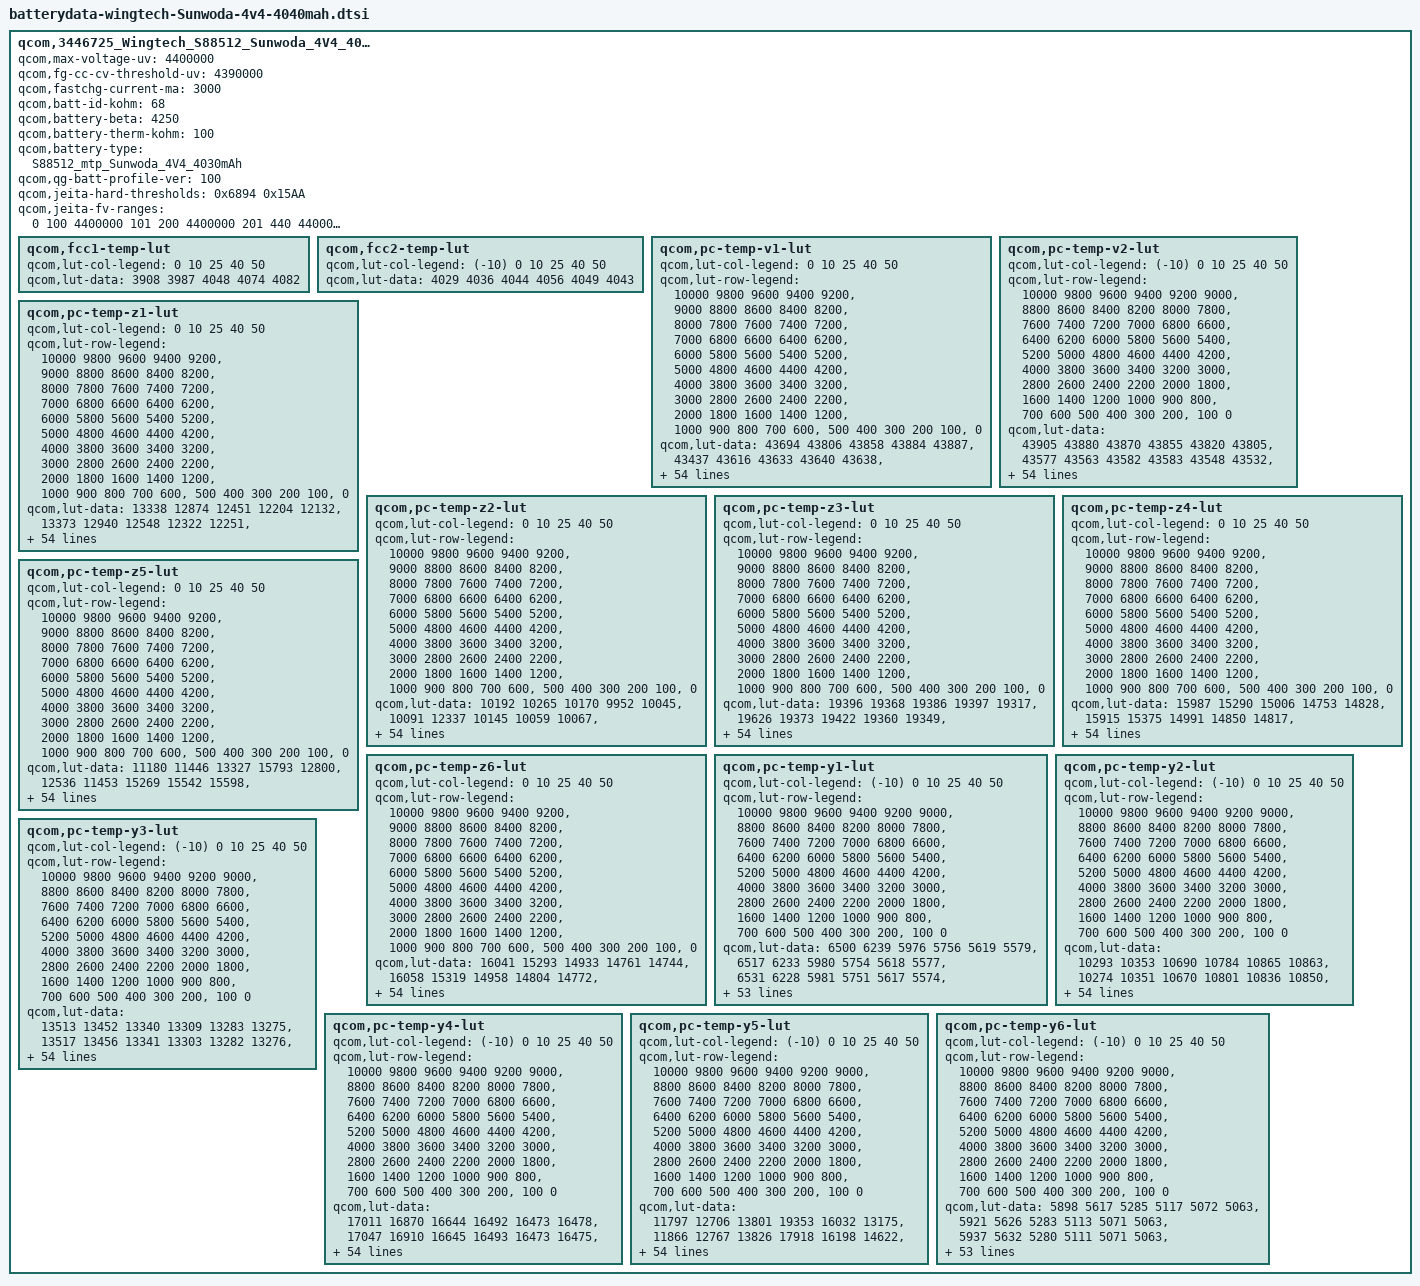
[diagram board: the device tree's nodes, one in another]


qcom,3446725_Wingtech_S88512_Sunwoda_4V4_4040mAh {
	qcom,max-voltage-uv = <4400000>;
	qcom,fg-cc-cv-threshold-uv = <4390000>;
	qcom,fastchg-current-ma = <3000>;
	qcom,batt-id-kohm = <68>;
	qcom,battery-beta = <4250>;
	qcom,battery-therm-kohm = <100>;

	qcom,battery-type = "S88512_mtp_Sunwoda_4V4_4030mAh";
	qcom,qg-batt-profile-ver = <100>;
	/* COLD = 0 DegC, HOT = 60 DegC */
	qcom,jeita-hard-thresholds = <0x6894 0x15AA>;
        qcom,jeita-fv-ranges = <0   100  4400000
                                101 200  4400000
                                201 440  4400000
                                441 580  4100000>;
	qcom,fcc1-temp-lut {
		qcom,lut-col-legend = <0 10 25 40 50>;
		qcom,lut-data = <3908 3987 4048 4074 4082>;
	};

	qcom,fcc2-temp-lut {
		qcom,lut-col-legend = <(-10) 0 10 25 40 50>;
		qcom,lut-data = <4029 4036 4044 4056 4049 4043>;
	};

	qcom,pc-temp-v1-lut {
		qcom,lut-col-legend = <0 10 25 40 50>;
		qcom,lut-row-legend = <10000 9800 9600 9400 9200>,
			<9000 8800 8600 8400 8200>,
			<8000 7800 7600 7400 7200>,
			<7000 6800 6600 6400 6200>,
			<6000 5800 5600 5400 5200>,
			<5000 4800 4600 4400 4200>,
			<4000 3800 3600 3400 3200>,
			<3000 2800 2600 2400 2200>,
			<2000 1800 1600 1400 1200>,
			<1000 900 800 700 600>,
			<500 400 300 200 100>,
			<0>;
		qcom,lut-data = <43694 43806 43858 43884 43887>,
			<43437 43616 43633 43640 43638>,
			<43187 43380 43403 43416 43414>,
			<42946 43129 43165 43189 43191>,
			<42711 42882 42930 42959 42965>,
			<42480 42631 42698 42726 42735>,
			<42253 42396 42467 42493 42503>,
			<42031 42174 42235 42261 42273>,
			<41815 41955 42004 42032 42045>,
			<41603 41729 41778 41806 41818>,
			<41403 41504 41556 41581 41593>,
			<41221 41301 41342 41361 41372>,
			<41036 41122 41139 41149 41155>,
			<40820 40933 40944 40948 40944>,
			<40584 40707 40740 40746 40739>,
			<40362 40473 40526 40538 40538>,
			<40155 40270 40323 40339 40345>,
			<39969 40087 40138 40158 40167>,
			<39818 39921 39964 39989 40000>,
			<39691 39786 39808 39826 39836>,
			<39561 39651 39668 39675 39681>,
			<39425 39448 39501 39507 39512>,
			<39279 39165 39244 39274 39286>,
			<39090 38954 38994 39028 39041>,
			<38858 38832 38848 38866 38872>,
			<38697 38738 38743 38749 38750>,
			<38607 38652 38645 38643 38641>,
			<38540 38577 38548 38538 38536>,
			<38483 38505 38459 38443 38440>,
			<38436 38434 38378 38357 38351>,
			<38392 38369 38306 38280 38270>,
			<38349 38312 38241 38210 38198>,
			<38309 38261 38184 38147 38134>,
			<38271 38215 38133 38088 38073>,
			<38237 38177 38090 38037 38014>,
			<38203 38140 38050 37988 37957>,
			<38173 38104 38009 37938 37896>,
			<38140 38068 37970 37890 37836>,
			<38087 38015 37918 37829 37765>,
			<38001 37929 37835 37740 37670>,
			<37899 37823 37729 37631 37559>,
			<37780 37708 37616 37516 37442>,
			<37642 37574 37485 37387 37314>,
			<37482 37412 37328 37234 37155>,
			<37335 37264 37182 37092 37017>,
			<37244 37167 37085 37002 36941>,
			<37213 37139 37057 36977 36917>,
			<37190 37118 37042 36958 36898>,
			<37176 37104 37025 36938 36879>,
			<37140 37064 36975 36875 36802>,
			<36908 36834 36730 36603 36508>,
			<36467 36401 36294 36159 36060>,
			<35892 35824 35715 35580 35480>,
			<35101 35034 34928 34787 34684>,
			<33856 33800 33689 33551 33441>,
			<30000 30000 30000 30000 30000>;
	};

	qcom,pc-temp-v2-lut {
		qcom,lut-col-legend = <(-10) 0 10 25 40 50>;
		qcom,lut-row-legend = <10000 9800 9600 9400 9200 9000>,
			<8800 8600 8400 8200 8000 7800>,
			<7600 7400 7200 7000 6800 6600>,
			<6400 6200 6000 5800 5600 5400>,
			<5200 5000 4800 4600 4400 4200>,
			<4000 3800 3600 3400 3200 3000>,
			<2800 2600 2400 2200 2000 1800>,
			<1600 1400 1200 1000 900 800>,
			<700 600 500 400 300 200>,
			<100 0>;
		qcom,lut-data = <43905 43880 43870 43855 43820 43805>,
			<43577 43563 43582 43583 43548 43532>,
			<43271 43267 43310 43322 43287 43272>,
			<42993 42992 43054 43072 43039 43025>,
			<42740 42740 42812 42834 42804 42793>,
			<42495 42494 42575 42598 42571 42561>,
			<42257 42251 42340 42364 42337 42327>,
			<42025 42015 42109 42133 42104 42095>,
			<41801 41788 41882 41904 41875 41866>,
			<41583 41568 41659 41677 41649 41640>,
			<41372 41355 41439 41453 41425 41416>,
			<41172 41152 41223 41231 41204 41197>,
			<40974 40952 41013 41015 40989 40982>,
			<40777 40757 40821 40815 40788 40775>,
			<40575 40563 40638 40622 40594 40574>,
			<40322 40345 40431 40419 40396 40379>,
			<39957 40087 40190 40203 40191 40190>,
			<39629 39837 39958 40005 39998 40008>,
			<39440 39627 39765 39846 39838 39842>,
			<39293 39432 39585 39694 39684 39680>,
			<39141 39239 39385 39496 39494 39488>,
			<38985 39042 39165 39247 39261 39261>,
			<38836 38865 38969 39026 39046 39050>,
			<38695 38711 38805 38846 38861 38866>,
			<38561 38572 38661 38690 38699 38704>,
			<38429 38445 38536 38561 38569 38572>,
			<38297 38328 38425 38452 38460 38461>,
			<38192 38223 38324 38352 38359 38360>,
			<38117 38125 38231 38261 38266 38265>,
			<38055 38040 38145 38178 38180 38178>,
			<37999 37981 38067 38102 38105 38100>,
			<37947 37935 37994 38030 38036 38028>,
			<37897 37892 37931 37962 37970 37961>,
			<37846 37852 37874 37897 37909 37902>,
			<37796 37812 37823 37834 37843 37835>,
			<37747 37770 37779 37772 37755 37734>,
			<37698 37727 37738 37708 37655 37612>,
			<37646 37678 37687 37636 37562 37506>,
			<37588 37621 37623 37554 37473 37413>,
			<37524 37553 37551 37473 37387 37325>,
			<37448 37464 37466 37400 37311 37246>,
			<37358 37356 37367 37313 37225 37160>,
			<37240 37235 37251 37195 37110 37047>,
			<37126 37098 37114 37062 36978 36912>,
			<37024 36952 36959 36924 36858 36799>,
			<36950 36871 36911 36892 36827 36770>,
			<36913 36838 36891 36875 36813 36757>,
			<36880 36808 36872 36854 36799 36742>,
			<36834 36763 36834 36821 36767 36709>,
			<36757 36676 36751 36728 36654 36581>,
			<36557 36455 36497 36416 36323 36227>,
			<36135 36007 36017 35915 35814 35712>,
			<35527 35377 35378 35257 35155 35046>,
			<34662 34511 34489 34334 34227 34127>,
			<33285 33205 33210 32889 32876 32707>,
			<27763 27651 27674 27756 27524 27449>;
	};

	qcom,pc-temp-z1-lut {
		qcom,lut-col-legend = <0 10 25 40 50>;
		qcom,lut-row-legend = <10000 9800 9600 9400 9200>,
			<9000 8800 8600 8400 8200>,
			<8000 7800 7600 7400 7200>,
			<7000 6800 6600 6400 6200>,
			<6000 5800 5600 5400 5200>,
			<5000 4800 4600 4400 4200>,
			<4000 3800 3600 3400 3200>,
			<3000 2800 2600 2400 2200>,
			<2000 1800 1600 1400 1200>,
			<1000 900 800 700 600>,
			<500 400 300 200 100>,
			<0>;
		qcom,lut-data = <13338 12874 12451 12204 12132>,
			<13373 12940 12548 12322 12251>,
			<13396 12959 12562 12331 12273>,
			<13404 12964 12564 12334 12275>,
			<13406 12960 12562 12335 12274>,
			<13404 12955 12557 12333 12274>,
			<13396 12948 12551 12332 12273>,
			<13387 12933 12544 12329 12273>,
			<13377 12922 12536 12326 12274>,
			<13367 12918 12532 12325 12274>,
			<13360 12914 12532 12325 12274>,
			<13356 12912 12532 12325 12274>,
			<13353 12914 12530 12324 12274>,
			<13346 12914 12528 12324 12273>,
			<13331 12897 12526 12323 12272>,
			<13315 12876 12522 12322 12273>,
			<13297 12874 12519 12322 12273>,
			<13283 12881 12521 12321 12273>,
			<13288 12886 12522 12321 12274>,
			<13305 12886 12524 12322 12275>,
			<13313 12886 12529 12324 12276>,
			<13307 12887 12531 12326 12278>,
			<13300 12890 12532 12327 12278>,
			<13307 12894 12533 12328 12279>,
			<13334 12898 12536 12330 12281>,
			<13346 12903 12540 12334 12286>,
			<13331 12904 12545 12338 12290>,
			<13315 12905 12553 12341 12292>,
			<13315 12906 12561 12345 12294>,
			<13320 12910 12565 12349 12297>,
			<13325 12913 12567 12353 12301>,
			<13329 12919 12569 12357 12305>,
			<13335 12926 12572 12361 12308>,
			<13337 12932 12575 12365 12311>,
			<13341 12939 12581 12370 12315>,
			<13344 12943 12589 12376 12320>,
			<13344 12945 12593 12381 12324>,
			<13346 12950 12595 12385 12328>,
			<13352 12954 12599 12389 12331>,
			<13361 12958 12605 12393 12335>,
			<13371 12961 12612 12397 12338>,
			<13387 12965 12617 12401 12341>,
			<13402 12973 12622 12404 12344>,
			<13422 12979 12627 12408 12347>,
			<13419 12983 12629 12412 12350>,
			<13410 12984 12632 12415 12351>,
			<13403 12992 12633 12415 12351>,
			<13416 12992 12634 12415 12353>,
			<13404 12975 12631 12419 12356>,
			<13413 12982 12635 12420 12361>,
			<13435 12992 12638 12428 12367>,
			<13428 13003 12655 12435 12372>,
			<13433 13018 12668 12446 12381>,
			<13449 13049 12680 12456 12391>,
			<13449 13049 12680 12456 12391>,
			<13449 13049 12680 12456 12391>;
	};

	qcom,pc-temp-z2-lut {
		qcom,lut-col-legend = <0 10 25 40 50>;
		qcom,lut-row-legend = <10000 9800 9600 9400 9200>,
			<9000 8800 8600 8400 8200>,
			<8000 7800 7600 7400 7200>,
			<7000 6800 6600 6400 6200>,
			<6000 5800 5600 5400 5200>,
			<5000 4800 4600 4400 4200>,
			<4000 3800 3600 3400 3200>,
			<3000 2800 2600 2400 2200>,
			<2000 1800 1600 1400 1200>,
			<1000 900 800 700 600>,
			<500 400 300 200 100>,
			<0>;
		qcom,lut-data = <10192 10265 10170 9952 10045>,
			<10091 12337 10145 10059 10067>,
			<10028 11693 10192 10034 10063>,
			<10013 10970 10199 10065 10046>,
			<10005 10521 10207 10092 10035>,
			<9995 10170 10408 10079 10034>,
			<9982 10128 10629 10050 10034>,
			<9970 10321 10538 10034 10031>,
			<9964 10461 10255 10022 10016>,
			<9959 10332 10174 10017 10005>,
			<9958 10114 10403 10017 10014>,
			<9960 10100 10602 10017 10032>,
			<9961 10272 10589 10019 10042>,
			<9960 10382 10555 10027 10049>,
			<9955 10291 10549 10033 10056>,
			<9954 10156 10563 10036 10065>,
			<9971 10136 10572 10037 10073>,
			<9997 10145 10423 10039 10077>,
			<10017 10157 10205 10043 10080>,
			<10037 10177 10176 10052 10087>,
			<10053 10196 10180 10085 10109>,
			<10065 10200 10187 10110 10132>,
			<10075 10201 10220 10118 10148>,
			<10086 10201 10255 10123 10160>,
			<10095 10200 10263 10119 10155>,
			<10105 10200 10266 10109 10112>,
			<10113 10202 10267 10101 10066>,
			<10121 10208 10265 10100 10021>,
			<10125 10211 10260 10098 9985>,
			<10128 10206 10246 10083 9976>,
			<10132 10201 10224 10055 9971>,
			<10140 10202 10220 10041 9971>,
			<10149 10205 10236 10036 9981>,
			<10153 10210 10253 10039 9999>,
			<10156 10219 10266 10061 10024>,
			<10160 10232 10278 10102 10059>,
			<10166 10244 10293 10132 10096>,
			<10174 10256 10310 10155 10139>,
			<10182 10269 10326 10178 10171>,
			<10193 10288 10347 10214 10190>,
			<10201 10300 10366 10246 10203>,
			<10204 10299 10375 10243 10197>,
			<10208 10297 10380 10229 10176>,
			<10225 10306 10381 10226 10177>,
			<10361 10382 10389 10233 10177>,
			<10446 10462 10421 10239 10164>,
			<10445 10457 10390 10263 10180>,
			<10448 10462 10400 10274 10181>,
			<10385 10489 10399 10289 10243>,
			<10301 10530 10469 10332 10269>,
			<10306 10581 10444 10215 10101>,
			<10204 10539 10438 10142 10035>,
			<10080 10486 10340 10100 9978>,
			<9898 10435 10329 10055 9920>,
			<9898 10435 10329 10055 9920>,
			<9898 10435 10329 10055 9920>;
	};

	qcom,pc-temp-z3-lut {
		qcom,lut-col-legend = <0 10 25 40 50>;
		qcom,lut-row-legend = <10000 9800 9600 9400 9200>,
			<9000 8800 8600 8400 8200>,
			<8000 7800 7600 7400 7200>,
			<7000 6800 6600 6400 6200>,
			<6000 5800 5600 5400 5200>,
			<5000 4800 4600 4400 4200>,
			<4000 3800 3600 3400 3200>,
			<3000 2800 2600 2400 2200>,
			<2000 1800 1600 1400 1200>,
			<1000 900 800 700 600>,
			<500 400 300 200 100>,
			<0>;
		qcom,lut-data = <19396 19368 19386 19397 19317>,
			<19626 19373 19422 19360 19349>,
			<19765 19461 19448 19385 19370>,
			<19796 19550 19458 19391 19376>,
			<19813 19584 19465 19394 19380>,
			<19816 19607 19473 19399 19385>,
			<19813 19623 19479 19402 19390>,
			<19807 19638 19476 19403 19392>,
			<19799 19644 19464 19402 19392>,
			<19784 19629 19461 19402 19392>,
			<19772 19602 19470 19400 19390>,
			<19760 19599 19477 19397 19387>,
			<19753 19609 19470 19393 19384>,
			<19755 19615 19460 19386 19381>,
			<19762 19600 19455 19384 19379>,
			<19764 19575 19454 19384 19378>,
			<19751 19559 19452 19384 19377>,
			<19732 19548 19443 19383 19374>,
			<19714 19541 19431 19380 19367>,
			<19694 19536 19427 19377 19362>,
			<19687 19534 19424 19371 19356>,
			<19693 19540 19423 19368 19353>,
			<19704 19564 19428 19370 19356>,
			<19717 19575 19434 19375 19363>,
			<19736 19565 19433 19381 19372>,
			<19743 19552 19427 19388 19389>,
			<19737 19548 19427 19396 19399>,
			<19726 19547 19444 19408 19400>,
			<19715 19547 19460 19416 19401>,
			<19704 19554 19461 19415 19400>,
			<19695 19561 19461 19410 19396>,
			<19688 19561 19461 19405 19390>,
			<19682 19558 19455 19401 19384>,
			<19680 19555 19449 19396 19377>,
			<19678 19551 19444 19390 19370>,
			<19676 19547 19440 19384 19363>,
			<19673 19544 19435 19379 19360>,
			<19668 19541 19430 19373 19357>,
			<19664 19538 19426 19370 19356>,
			<19659 19534 19423 19373 19360>,
			<19654 19530 19420 19376 19365>,
			<19651 19525 19417 19375 19366>,
			<19647 19520 19414 19374 19366>,
			<19632 19516 19412 19375 19371>,
			<19578 19493 19402 19374 19373>,
			<19524 19460 19388 19363 19359>,
			<19516 19459 19388 19353 19350>,
			<19510 19460 19374 19347 19342>,
			<19431 19431 19370 19345 19328>,
			<19349 19428 19361 19343 19332>,
			<19379 19424 19372 19364 19358>,
			<19376 19389 19367 19371 19361>,
			<19347 19372 19379 19370 19363>,
			<19344 19360 19374 19370 19365>,
			<19344 19360 19374 19370 19365>,
			<19344 19360 19374 19370 19365>;
	};

	qcom,pc-temp-z4-lut {
		qcom,lut-col-legend = <0 10 25 40 50>;
		qcom,lut-row-legend = <10000 9800 9600 9400 9200>,
			<9000 8800 8600 8400 8200>,
			<8000 7800 7600 7400 7200>,
			<7000 6800 6600 6400 6200>,
			<6000 5800 5600 5400 5200>,
			<5000 4800 4600 4400 4200>,
			<4000 3800 3600 3400 3200>,
			<3000 2800 2600 2400 2200>,
			<2000 1800 1600 1400 1200>,
			<1000 900 800 700 600>,
			<500 400 300 200 100>,
			<0>;
		qcom,lut-data = <15987 15290 15006 14753 14828>,
			<15915 15375 14991 14850 14817>,
			<15812 15276 15026 14897 14863>,
			<15663 15158 14970 14875 14850>,
			<15470 15083 14913 14847 14830>,
			<15325 15017 14855 14826 14813>,
			<15219 14942 14808 14806 14794>,
			<15136 14846 14793 14787 14777>,
			<15075 14794 14781 14770 14760>,
			<15028 14795 14769 14754 14746>,
			<14985 14798 14729 14742 14736>,
			<14941 14788 14696 14731 14728>,
			<14904 14731 14691 14723 14722>,
			<14876 14695 14689 14718 14717>,
			<14853 14719 14688 14713 14712>,
			<14838 14755 14689 14709 14707>,
			<14828 14760 14689 14705 14702>,
			<14820 14755 14692 14697 14697>,
			<14811 14748 14695 14687 14690>,
			<14803 14734 14692 14684 14689>,
			<14795 14719 14688 14686 14690>,
			<14784 14740 14688 14689 14691>,
			<14775 14827 14761 14740 14732>,
			<14796 14870 14841 14815 14801>,
			<14865 14871 14845 14822 14809>,
			<14897 14871 14834 14799 14777>,
			<14895 14864 14819 14773 14748>,
			<14890 14841 14785 14747 14732>,
			<14881 14817 14752 14725 14719>,
			<14867 14794 14736 14714 14711>,
			<14852 14774 14725 14708 14705>,
			<14839 14763 14718 14703 14699>,
			<14826 14755 14715 14697 14693>,
			<14814 14750 14712 14694 14689>,
			<14803 14747 14711 14694 14688>,
			<14793 14744 14709 14694 14687>,
			<14783 14741 14709 14694 14688>,
			<14776 14739 14709 14694 14688>,
			<14775 14739 14709 14694 14690>,
			<14777 14744 14715 14699 14695>,
			<14778 14749 14722 14705 14700>,
			<14775 14746 14720 14702 14698>,
			<14771 14740 14712 14695 14690>,
			<14767 14736 14712 14696 14693>,
			<14747 14722 14709 14693 14692>,
			<14745 14705 14687 14672 14664>,
			<14744 14699 14678 14671 14661>,
			<14743 14688 14679 14661 14652>,
			<14824 14710 14671 14643 14642>,
			<14905 14710 14680 14644 14636>,
			<14879 14725 14691 14658 14657>,
			<14902 14771 14701 14661 14666>,
			<14939 14793 14694 14667 14669>,
			<14951 14811 14702 14671 14670>,
			<14951 14811 14702 14671 14670>,
			<14951 14811 14702 14671 14670>;
	};

	qcom,pc-temp-z5-lut {
		qcom,lut-col-legend = <0 10 25 40 50>;
		qcom,lut-row-legend = <10000 9800 9600 9400 9200>,
			<9000 8800 8600 8400 8200>,
			<8000 7800 7600 7400 7200>,
			<7000 6800 6600 6400 6200>,
			<6000 5800 5600 5400 5200>,
			<5000 4800 4600 4400 4200>,
			<4000 3800 3600 3400 3200>,
			<3000 2800 2600 2400 2200>,
			<2000 1800 1600 1400 1200>,
			<1000 900 800 700 600>,
			<500 400 300 200 100>,
			<0>;
		qcom,lut-data = <11180 11446 13327 15793 12800>,
			<12536 11453 15269 15542 15598>,
			<13561 12291 16216 16661 17113>,
			<14198 13497 16903 17095 17558>,
			<14673 14818 17570 17515 17942>,
			<15085 16372 18436 18000 18561>,
			<15480 17822 19145 18504 19312>,
			<15798 19366 19359 18958 19932>,
			<15987 20265 19483 19355 20422>,
			<16127 20363 20073 19815 20916>,
			<16347 20408 24396 20621 21519>,
			<16764 21182 28028 21330 22150>,
			<17398 24704 27621 21320 22675>,
			<18764 26926 26647 21061 23146>,
			<20977 26233 26319 20991 23788>,
			<21849 24980 26283 21705 25233>,
			<21853 23912 26233 22791 26481>,
			<21792 22232 25345 23961 26482>,
			<21522 21403 24295 25224 26227>,
			<20923 22132 24965 25721 25981>,
			<20747 23835 26575 25861 25704>,
			<22971 28389 27278 25798 25263>,
			<26908 39001 27011 24257 23460>,
			<32432 43797 26425 21626 20833>,
			<40474 36182 24306 19904 20157>,
			<43629 26416 19990 18492 20007>,
			<39728 23583 18653 18034 19975>,
			<34111 22164 20519 20277 21367>,
			<30722 21835 23152 23377 23568>,
			<28039 23544 25626 24906 25086>,
			<26658 25890 28213 25968 26386>,
			<26066 27452 30169 27167 26946>,
			<25719 28923 31779 28841 27105>,
			<25862 29808 32804 29965 27156>,
			<26580 30419 33343 30175 27175>,
			<27203 30819 33674 30289 27181>,
			<27701 30964 33326 29928 27069>,
			<28207 31065 31466 27840 26807>,
			<28596 30972 29483 26349 26651>,
			<29021 30142 27614 26079 26706>,
			<29213 28983 25940 25873 26790>,
			<28907 27577 24781 25232 26616>,
			<28375 26431 23848 24219 26143>,
			<27336 26418 22986 24109 27954>,
			<26588 25886 21867 23881 29548>,
			<22209 23945 21624 22133 24894>,
			<21328 23774 22142 19489 20895>,
			<20699 24980 19320 19407 20199>,
			<16273 19043 19189 22112 19602>,
			<12417 18946 17657 20845 23007>,
			<13249 17818 17589 21506 22887>,
			<12855 14647 16121 21103 20486>,
			<12104 13634 17197 19330 18857>,
			<11900 12995 15949 17583 17143>,
			<11900 12995 15949 17583 17143>,
			<11900 12995 15949 17583 17143>;
	};

	qcom,pc-temp-z6-lut {
		qcom,lut-col-legend = <0 10 25 40 50>;
		qcom,lut-row-legend = <10000 9800 9600 9400 9200>,
			<9000 8800 8600 8400 8200>,
			<8000 7800 7600 7400 7200>,
			<7000 6800 6600 6400 6200>,
			<6000 5800 5600 5400 5200>,
			<5000 4800 4600 4400 4200>,
			<4000 3800 3600 3400 3200>,
			<3000 2800 2600 2400 2200>,
			<2000 1800 1600 1400 1200>,
			<1000 900 800 700 600>,
			<500 400 300 200 100>,
			<0>;
		qcom,lut-data = <16041 15293 14933 14761 14744>,
			<16058 15319 14958 14804 14772>,
			<16040 15303 14983 14837 14804>,
			<15975 15290 14963 14831 14802>,
			<15852 15262 14942 14823 14798>,
			<15753 15226 14921 14816 14793>,
			<15679 15190 14902 14809 14788>,
			<15616 15152 14888 14801 14782>,
			<15565 15120 14876 14793 14776>,
			<15522 15101 14865 14786 14770>,
			<15481 15085 14854 14779 14764>,
			<15442 15067 14844 14773 14758>,
			<15408 15046 14836 14767 14754>,
			<15381 15032 14829 14760 14750>,
			<15358 15026 14826 14756 14747>,
			<15338 15022 14825 14754 14744>,
			<15318 15016 14823 14752 14741>,
			<15302 15008 14819 14748 14736>,
			<15289 15001 14813 14742 14730>,
			<15279 14995 14810 14739 14726>,
			<15275 14990 14807 14738 14724>,
			<15277 15003 14807 14737 14723>,
			<15283 15053 14842 14760 14742>,
			<15301 15078 14880 14796 14777>,
			<15342 15076 14882 14801 14783>,
			<15360 15071 14876 14797 14779>,
			<15357 15065 14871 14792 14775>,
			<15351 15057 14866 14788 14771>,
			<15343 15050 14862 14783 14766>,
			<15332 15046 14858 14779 14761>,
			<15323 15043 14854 14774 14757>,
			<15316 15039 14850 14769 14752>,
			<15311 15037 14847 14765 14747>,
			<15307 15035 14844 14762 14741>,
			<15305 15034 14842 14759 14737>,
			<15303 15033 14841 14756 14733>,
			<15303 15033 14839 14754 14732>,
			<15303 15034 14838 14751 14731>,
			<15304 15036 14837 14750 14731>,
			<15310 15040 14840 14753 14735>,
			<15316 15043 14843 14759 14741>,
			<15323 15043 14842 14758 14740>,
			<15327 15043 14839 14755 14738>,
			<15327 15043 14839 14756 14741>,
			<15310 15035 14836 14755 14743>,
			<15290 15017 14821 14741 14724>,
			<15286 15014 14818 14736 14718>,
			<15282 15011 14811 14728 14710>,
			<15278 15007 14806 14719 14698>,
			<15278 15009 14807 14720 14699>,
			<15290 15019 14820 14738 14723>,
			<15307 15027 14825 14746 14731>,
			<15321 15036 14831 14750 14736>,
			<15347 15050 14838 14755 14741>,
			<15347 15050 14838 14755 14741>,
			<15347 15050 14838 14755 14741>;
	};

	qcom,pc-temp-y1-lut {
		qcom,lut-col-legend = <(-10) 0 10 25 40 50>;
		qcom,lut-row-legend = <10000 9800 9600 9400 9200 9000>,
			<8800 8600 8400 8200 8000 7800>,
			<7600 7400 7200 7000 6800 6600>,
			<6400 6200 6000 5800 5600 5400>,
			<5200 5000 4800 4600 4400 4200>,
			<4000 3800 3600 3400 3200 3000>,
			<2800 2600 2400 2200 2000 1800>,
			<1600 1400 1200 1000 900 800>,
			<700 600 500 400 300 200>,
			<100 0>;
		qcom,lut-data = <6500 6239 5976 5756 5619 5579>,
			<6517 6233 5980 5754 5618 5577>,
			<6531 6228 5981 5751 5617 5574>,
			<6542 6223 5982 5747 5616 5572>,
			<6550 6218 5981 5744 5614 5570>,
			<6552 6214 5980 5743 5612 5569>,
			<6547 6208 5977 5742 5610 5567>,
			<6542 6204 5974 5741 5608 5566>,
			<6546 6206 5971 5740 5606 5566>,
			<6558 6213 5968 5738 5603 5565>,
			<6562 6218 5967 5735 5601 5564>,
			<6545 6220 5967 5733 5600 5562>,
			<6527 6219 5967 5730 5599 5560>,
			<6531 6214 5966 5729 5599 5559>,
			<6542 6206 5965 5728 5598 5559>,
			<6546 6203 5964 5728 5598 5558>,
			<6553 6203 5964 5729 5598 5558>,
			<6559 6205 5964 5731 5598 5558>,
			<6561 6212 5965 5732 5597 5559>,
			<6561 6222 5969 5734 5596 5559>,
			<6561 6227 5970 5734 5596 5559>,
			<6565 6231 5973 5733 5597 5559>,
			<6568 6233 5974 5733 5598 5559>,
			<6570 6229 5972 5737 5599 5561>,
			<6572 6225 5970 5741 5600 5563>,
			<6569 6223 5970 5742 5601 5564>,
			<6567 6220 5971 5743 5603 5565>,
			<6566 6219 5971 5745 5605 5566>,
			<6594 6218 5971 5749 5607 5568>,
			<6628 6218 5972 5753 5610 5571>,
			<6616 6217 6009 5757 5614 5573>,
			<6568 6217 6095 5761 5618 5575>,
			<6548 6218 6112 5763 5620 5577>,
			<6554 6221 6034 5763 5623 5580>,
			<6560 6223 5974 5764 5626 5583>,
			<6549 6221 5980 5769 5627 5584>,
			<6527 6214 5990 5775 5628 5585>,
			<6520 6211 5992 5776 5629 5586>,
			<6529 6208 5988 5774 5632 5590>,
			<6536 6206 5985 5772 5634 5593>,
			<6543 6208 5983 5772 5636 5593>,
			<6552 6212 5982 5773 5638 5594>,
			<6528 6220 5985 5774 5636 5595>,
			<6543 6217 5988 5784 5640 5597>,
			<6530 6219 6000 5787 5644 5600>,
			<6543 6221 6000 5785 5645 5603>,
			<6535 6228 5995 5787 5644 5602>,
			<6545 6223 6003 5847 5645 5601>,
			<6557 6217 6003 5800 5648 5601>,
			<6546 6215 6000 5789 5647 5603>,
			<6526 6213 6013 5789 5650 5607>,
			<6553 6223 6024 5798 5654 5610>,
			<6552 6230 6023 5805 5659 5616>,
			<6581 6240 6035 5820 5671 5622>,
			<6581 6240 6035 5820 5671 5622>,
			<6581 6240 6035 5820 5671 5622>;
	};

	qcom,pc-temp-y2-lut {
		qcom,lut-col-legend = <(-10) 0 10 25 40 50>;
		qcom,lut-row-legend = <10000 9800 9600 9400 9200 9000>,
			<8800 8600 8400 8200 8000 7800>,
			<7600 7400 7200 7000 6800 6600>,
			<6400 6200 6000 5800 5600 5400>,
			<5200 5000 4800 4600 4400 4200>,
			<4000 3800 3600 3400 3200 3000>,
			<2800 2600 2400 2200 2000 1800>,
			<1600 1400 1200 1000 900 800>,
			<700 600 500 400 300 200>,
			<100 0>;
		qcom,lut-data = <10293 10353 10690 10784 10865 10863>,
			<10274 10351 10670 10801 10836 10850>,
			<10266 10351 10649 10808 10800 10832>,
			<10266 10352 10630 10808 10765 10812>,
			<10272 10354 10614 10802 10740 10795>,
			<10281 10356 10602 10794 10732 10786>,
			<10302 10359 10595 10760 10738 10783>,
			<10323 10363 10589 10721 10746 10779>,
			<10323 10366 10585 10707 10742 10759>,
			<10320 10370 10581 10699 10726 10715>,
			<10322 10378 10580 10699 10719 10697>,
			<10406 10408 10587 10707 10712 10715>,
			<10504 10455 10598 10712 10699 10731>,
			<10536 10525 10614 10703 10673 10714>,
			<10556 10612 10641 10690 10638 10679>,
			<10569 10639 10677 10693 10635 10672>,
			<10577 10641 10737 10734 10679 10689>,
			<10587 10644 10780 10790 10710 10702>,
			<10605 10663 10790 10872 10705 10688>,
			<10632 10700 10796 10950 10697 10663>,
			<10654 10728 10811 10951 10706 10669>,
			<10678 10751 10843 10911 10758 10722>,
			<10690 10773 10879 10892 10809 10772>,
			<10684 10801 10918 10935 10847 10803>,
			<10667 10824 10957 10995 10879 10826>,
			<10523 10824 10985 11031 10902 10839>,
			<9991 10808 11009 11058 10920 10851>,
			<9708 10774 11025 11067 10930 10859>,
			<9700 10528 11036 11065 10920 10880>,
			<9695 10229 11046 11064 10912 10908>,
			<9689 10101 11058 11089 10949 10929>,
			<9683 9990 11071 11137 11024 10953>,
			<9678 9911 11079 11153 11046 10971>,
			<9676 9843 11085 11156 11020 10997>,
			<9673 9790 11088 11159 10998 11013>,
			<9671 9759 11072 11173 10999 11002>,
			<9668 9738 11036 11191 11002 10983>,
			<9666 9721 11002 11194 11007 10980>,
			<9664 9707 10962 11189 11020 10982>,
			<9663 9696 10921 11186 11027 10979>,
			<9661 9686 10886 11189 11008 10958>,
			<9660 9678 10846 11184 10995 10938>,
			<9659 9672 10781 11126 10986 10932>,
			<9658 9667 10738 11112 10996 10920>,
			<9657 9665 10406 11082 11023 10883>,
			<9656 9661 10609 11067 10927 10818>,
			<9656 9660 10569 11059 10909 10756>,
			<9655 9658 10563 11038 10884 10726>,
			<9655 9657 10517 11029 10848 10740>,
			<9654 9656 10490 11016 10838 10731>,
			<9654 9655 10446 10966 10827 10692>,
			<9653 9654 10358 10907 10771 10645>,
			<9653 9653 10292 10840 10699 10534>,
			<9652 9652 9954 10779 10543 10388>,
			<9652 9652 9954 10779 10543 10388>,
			<9652 9652 9954 10779 10543 10388>;
	};

	qcom,pc-temp-y3-lut {
		qcom,lut-col-legend = <(-10) 0 10 25 40 50>;
		qcom,lut-row-legend = <10000 9800 9600 9400 9200 9000>,
			<8800 8600 8400 8200 8000 7800>,
			<7600 7400 7200 7000 6800 6600>,
			<6400 6200 6000 5800 5600 5400>,
			<5200 5000 4800 4600 4400 4200>,
			<4000 3800 3600 3400 3200 3000>,
			<2800 2600 2400 2200 2000 1800>,
			<1600 1400 1200 1000 900 800>,
			<700 600 500 400 300 200>,
			<100 0>;
		qcom,lut-data = <13513 13452 13340 13309 13283 13275>,
			<13517 13456 13341 13303 13282 13276>,
			<13526 13461 13342 13298 13282 13277>,
			<13536 13466 13343 13294 13281 13279>,
			<13544 13470 13345 13292 13281 13279>,
			<13547 13472 13346 13291 13281 13280>,
			<13547 13473 13347 13293 13281 13280>,
			<13547 13474 13348 13295 13281 13279>,
			<13551 13475 13348 13296 13281 13280>,
			<13567 13477 13349 13296 13282 13280>,
			<13573 13477 13350 13297 13282 13281>,
			<13559 13474 13353 13297 13282 13280>,
			<13539 13469 13357 13298 13282 13280>,
			<13526 13461 13359 13298 13284 13280>,
			<13513 13450 13361 13298 13288 13281>,
			<13499 13444 13361 13299 13289 13282>,
			<13481 13440 13357 13302 13289 13285>,
			<13465 13437 13352 13306 13290 13286>,
			<13454 13427 13350 13309 13291 13286>,
			<13445 13414 13348 13312 13292 13286>,
			<13435 13401 13344 13311 13292 13286>,
			<13425 13389 13336 13305 13290 13285>,
			<13417 13378 13329 13300 13288 13283>,
			<13411 13370 13323 13295 13285 13281>,
			<13406 13363 13318 13292 13282 13279>,
			<13385 13357 13317 13290 13282 13278>,
			<13327 13353 13316 13290 13281 13278>,
			<13298 13346 13315 13289 13281 13278>,
			<13302 13305 13314 13290 13280 13278>,
			<13310 13264 13313 13291 13280 13278>,
			<13321 13262 13313 13291 13281 13278>,
			<13337 13263 13314 13291 13282 13278>,
			<13352 13264 13314 13291 13282 13279>,
			<13363 13267 13313 13290 13282 13279>,
			<13375 13271 13312 13289 13281 13280>,
			<13394 13275 13312 13290 13280 13279>,
			<13420 13281 13312 13291 13279 13277>,
			<13448 13288 13312 13289 13279 13277>,
			<13477 13299 13311 13285 13279 13277>,
			<13508 13312 13311 13282 13279 13277>,
			<13544 13329 13312 13288 13279 13278>,
			<13583 13352 13314 13291 13280 13279>,
			<13621 13385 13319 13290 13280 13280>,
			<13683 13432 13322 13290 13281 13279>,
			<13696 13445 13307 13285 13279 13278>,
			<13803 13533 13326 13292 13282 13282>,
			<13857 13579 13329 13293 13284 13284>,
			<13940 13654 13337 13295 13290 13288>,
			<14027 13735 13343 13301 13293 13290>,
			<14133 13830 13354 13305 13291 13289>,
			<14257 13941 13359 13302 13288 13286>,
			<14429 14090 13365 13303 13288 13286>,
			<14737 14342 13380 13309 13294 13292>,
			<15173 14690 13411 13317 13299 13297>,
			<15173 14690 13411 13317 13299 13297>,
			<15173 14690 13411 13317 13299 13297>;
	};

	qcom,pc-temp-y4-lut {
		qcom,lut-col-legend = <(-10) 0 10 25 40 50>;
		qcom,lut-row-legend = <10000 9800 9600 9400 9200 9000>,
			<8800 8600 8400 8200 8000 7800>,
			<7600 7400 7200 7000 6800 6600>,
			<6400 6200 6000 5800 5600 5400>,
			<5200 5000 4800 4600 4400 4200>,
			<4000 3800 3600 3400 3200 3000>,
			<2800 2600 2400 2200 2000 1800>,
			<1600 1400 1200 1000 900 800>,
			<700 600 500 400 300 200>,
			<100 0>;
		qcom,lut-data = <17011 16870 16644 16492 16473 16478>,
			<17047 16910 16645 16493 16473 16475>,
			<17095 16951 16644 16496 16472 16473>,
			<17145 16987 16643 16498 16472 16472>,
			<17186 17012 16641 16500 16472 16471>,
			<17206 17020 16640 16501 16472 16471>,
			<17214 17010 16636 16501 16473 16471>,
			<17218 16999 16634 16502 16474 16472>,
			<17214 16998 16635 16504 16476 16473>,
			<17199 16999 16640 16509 16478 16474>,
			<17196 17003 16646 16515 16481 16475>,
			<17273 17036 16651 16521 16486 16478>,
			<17375 17092 16660 16530 16491 16481>,
			<17444 17182 16692 16542 16497 16485>,
			<17503 17299 16752 16557 16502 16489>,
			<17491 17320 16793 16572 16508 16494>,
			<17219 17216 16822 16583 16514 16498>,
			<16995 17102 16836 16599 16522 16505>,
			<16996 17044 16829 16645 16548 16523>,
			<17005 16997 16811 16695 16579 16545>,
			<17003 16941 16772 16685 16580 16547>,
			<16968 16874 16676 16612 16557 16533>,
			<16924 16821 16609 16552 16532 16517>,
			<16867 16790 16584 16513 16500 16496>,
			<16814 16765 16569 16489 16474 16477>,
			<16815 16731 16565 16487 16470 16473>,
			<16850 16688 16562 16487 16470 16471>,
			<16869 16673 16561 16487 16469 16471>,
			<16864 16708 16564 16491 16473 16472>,
			<16857 16750 16566 16497 16478 16475>,
			<16855 16761 16564 16504 16484 16479>,
			<16854 16766 16557 16512 16492 16486>,
			<16854 16770 16553 16518 16501 16496>,
			<16861 16775 16550 16522 16514 16511>,
			<16868 16780 16549 16524 16521 16520>,
			<16871 16787 16557 16518 16508 16506>,
			<16873 16797 16573 16505 16485 16478>,
			<16876 16806 16577 16496 16474 16470>,
			<16881 16820 16578 16489 16468 16468>,
			<16884 16828 16579 16486 16466 16468>,
			<16884 16813 16583 16491 16475 16478>,
			<16883 16796 16590 16496 16482 16486>,
			<16872 16791 16601 16499 16480 16483>,
			<16852 16785 16610 16502 16475 16473>,
			<16846 16774 16611 16487 16455 16447>,
			<16850 16783 16614 16500 16471 16469>,
			<16878 16809 16637 16515 16492 16501>,
			<16907 16841 16663 16537 16528 16550>,
			<16962 16894 16704 16575 16579 16595>,
			<17026 16964 16762 16608 16563 16560>,
			<17051 16995 16767 16551 16497 16489>,
			<17009 16994 16766 16554 16491 16486>,
			<17008 17036 16815 16589 16505 16495>,
			<17083 17165 16925 16665 16554 16550>,
			<17083 17165 16925 16665 16554 16550>,
			<17083 17165 16925 16665 16554 16550>;
	};

	qcom,pc-temp-y5-lut {
		qcom,lut-col-legend = <(-10) 0 10 25 40 50>;
		qcom,lut-row-legend = <10000 9800 9600 9400 9200 9000>,
			<8800 8600 8400 8200 8000 7800>,
			<7600 7400 7200 7000 6800 6600>,
			<6400 6200 6000 5800 5600 5400>,
			<5200 5000 4800 4600 4400 4200>,
			<4000 3800 3600 3400 3200 3000>,
			<2800 2600 2400 2200 2000 1800>,
			<1600 1400 1200 1000 900 800>,
			<700 600 500 400 300 200>,
			<100 0>;
		qcom,lut-data = <11797 12706 13801 19353 16032 13175>,
			<11866 12767 13826 17918 16198 14622>,
			<11939 12880 13856 16465 16066 15604>,
			<12012 13015 13888 15183 15767 16203>,
			<12077 13138 13925 14259 15434 16496>,
			<12130 13220 13963 13883 15192 16557>,
			<12186 13284 13971 14062 14837 16156>,
			<12273 13352 13958 14295 14508 15617>,
			<12550 13485 13903 14160 14427 15414>,
			<13130 13742 13745 13897 14287 15261>,
			<13335 13792 13693 13686 14117 15032>,
			<12887 12991 13809 13525 13673 14536>,
			<12438 12216 13917 13366 13318 14078>,
			<13150 12512 13702 13054 13554 13871>,
			<14920 13430 13226 12642 14070 13713>,
			<15424 14273 13128 12588 14180 13726>,
			<14869 15164 13442 12906 14000 14111>,
			<14377 15669 13925 13344 13863 14395>,
			<14302 15596 14850 13826 13859 14076>,
			<14263 15442 15938 14453 13886 13548>,
			<14284 15353 16228 15423 14294 13680>,
			<14492 15261 16292 16917 15935 14882>,
			<14803 15215 16267 17540 16920 15864>,
			<15499 15233 15714 16798 17024 16394>,
			<16282 15290 15050 15862 17022 16769>,
			<15663 15622 15032 15537 16990 16792>,
			<12504 16597 15205 15312 16901 16649>,
			<10842 16971 15284 15347 16706 16466>,
			<10856 14229 15341 15959 16055 16185>,
			<10886 11156 15486 16507 15506 15891>,
			<10972 10919 16169 16588 15763 15677>,
			<11152 10978 17441 16631 16403 15513>,
			<11220 11052 17778 16672 16635 15550>,
			<11182 11177 17362 16733 16497 15986>,
			<11144 11312 16837 16836 16363 16404>,
			<11190 11412 16423 17631 16506 16549>,
			<11327 11499 16017 18692 16753 16634>,
			<11450 11572 15634 18228 16805 16738>,
			<11572 11663 15215 15761 16803 16971>,
			<11648 11717 14920 14607 16742 17110>,
			<11657 11742 14654 16465 16442 17054>,
			<11659 11768 14512 17523 16162 16990>,
			<11319 11667 14895 16842 16018 17024>,
			<11223 11674 14966 16336 16679 17632>,
			<10952 11370 12727 14869 16525 17836>,
			<11242 11681 14531 16500 15354 16412>,
			<11111 11557 14345 15527 15432 15386>,
			<11266 11690 14490 15009 15946 14854>,
			<11299 11701 14123 15552 15254 14303>,
			<11491 11817 14300 15663 14860 14775>,
			<11517 12022 14574 16738 15452 15187>,
			<11279 11951 14496 16682 15822 15012>,
			<11297 11844 14470 17203 17576 16485>,
			<11214 11669 13672 16953 17997 18233>,
			<11214 11669 13672 16953 17997 18233>,
			<11214 11669 13672 16953 17997 18233>;
	};

	qcom,pc-temp-y6-lut {
		qcom,lut-col-legend = <(-10) 0 10 25 40 50>;
		qcom,lut-row-legend = <10000 9800 9600 9400 9200 9000>,
			<8800 8600 8400 8200 8000 7800>,
			<7600 7400 7200 7000 6800 6600>,
			<6400 6200 6000 5800 5600 5400>,
			<5200 5000 4800 4600 4400 4200>,
			<4000 3800 3600 3400 3200 3000>,
			<2800 2600 2400 2200 2000 1800>,
			<1600 1400 1200 1000 900 800>,
			<700 600 500 400 300 200>,
			<100 0>;
		qcom,lut-data = <5898 5617 5285 5117 5072 5063>,
			<5921 5626 5283 5113 5071 5063>,
			<5937 5632 5280 5111 5071 5063>,
			<5946 5634 5277 5108 5070 5063>,
			<5950 5635 5274 5107 5070 5064>,
			<5951 5635 5271 5106 5070 5064>,
			<5945 5627 5267 5107 5070 5064>,
			<5936 5615 5263 5108 5070 5064>,
			<5932 5609 5261 5109 5071 5064>,
			<5929 5604 5260 5110 5072 5065>,
			<5929 5603 5259 5112 5073 5066>,
			<5935 5606 5260 5114 5074 5066>,
			<5943 5611 5263 5116 5075 5067>,
			<5950 5626 5272 5119 5078 5068>,
			<5957 5650 5288 5124 5082 5070>,
			<5950 5653 5297 5129 5085 5072>,
			<5872 5625 5302 5134 5087 5075>,
			<5807 5592 5304 5141 5089 5078>,
			<5809 5571 5301 5156 5097 5083>,
			<5813 5551 5294 5173 5107 5089>,
			<5813 5529 5279 5169 5107 5089>,
			<5804 5503 5247 5144 5099 5084>,
			<5794 5484 5223 5122 5089 5078>,
			<5789 5475 5212 5108 5078 5070>,
			<5784 5468 5206 5099 5068 5063>,
			<5780 5463 5206 5098 5067 5062>,
			<5776 5459 5206 5098 5067 5061>,
			<5774 5458 5207 5098 5067 5061>,
			<5791 5458 5209 5100 5067 5062>,
			<5820 5460 5211 5104 5069 5063>,
			<5846 5468 5213 5107 5071 5064>,
			<5873 5491 5215 5109 5075 5066>,
			<5901 5515 5217 5112 5078 5069>,
			<5928 5538 5219 5113 5081 5074>,
			<5955 5563 5222 5114 5083 5077>,
			<5985 5590 5228 5113 5079 5073>,
			<6017 5619 5236 5111 5072 5064>,
			<6052 5651 5242 5108 5069 5062>,
			<6089 5686 5246 5104 5068 5061>,
			<6128 5724 5251 5102 5067 5061>,
			<6169 5761 5259 5107 5071 5065>,
			<6210 5803 5270 5112 5073 5069>,
			<6251 5855 5286 5113 5073 5068>,
			<6308 5921 5304 5115 5072 5066>,
			<6327 5951 5297 5109 5065 5057>,
			<6419 6054 5330 5119 5073 5067>,
			<6474 6112 5350 5125 5081 5078>,
			<6548 6191 5376 5133 5095 5095>,
			<6633 6279 5408 5149 5112 5110>,
			<6738 6381 5452 5161 5106 5099>,
			<6843 6489 5477 5144 5085 5077>,
			<6968 6613 5510 5148 5085 5076>,
			<7213 6826 5587 5166 5094 5084>,
			<7581 7133 5697 5197 5113 5106>,
			<7581 7133 5697 5197 5113 5106>,
			<7581 7133 5697 5197 5113 5106>;
	};

};
